# jv32_soc: IP-XACT component
VLNV kuoping:jv32:jv32_soc:1.2

## Address spaces and blocks
UART.uart_regs: base 0x20010000, range 0x20, width 32, register
CLIC.clint_regs: base 0x02000000, range 0x5000, width 32, register
MAGIC.magic_regs: base 0x40000000, range 0x08, width 32, register
CSR.csr_regs: base 0x000, range 0x1000, width 32, register

## Registers
Registers are 32-bit, read-write, no defined reset value unless marked. A register's access mark holds for its fields unless they carry their own. Offsets are from the block's base; lines under a group give offsets from that group; [hi:lo] are bit positions; {n}, {i} and the like mark numbered series; 'fields as' and 'values as' point back to an identical list; <NAME> marks a mode.

## UART.uart_regs
Base 0x20010000
0x00 DATA — TX FIFO write (write) / RX FIFO read (read)
  [7:0] DATA — Write: push byte to TX FIFO; Read: pop byte from RX FIFO
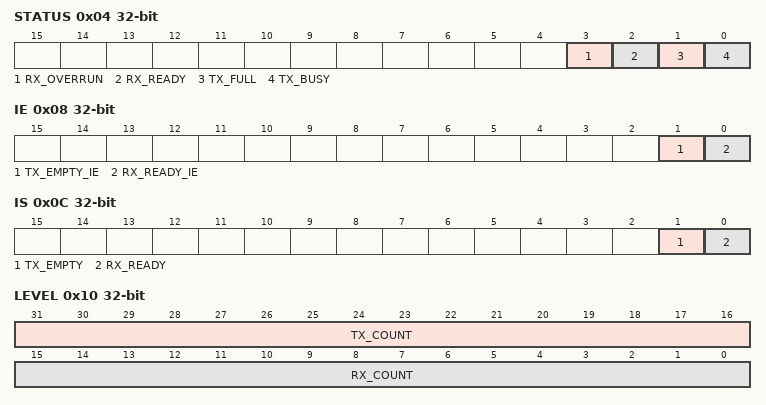
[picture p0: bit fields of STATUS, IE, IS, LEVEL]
0x04 STATUS ro — UART status flags (read-only)
  [3] RX_OVERRUN — 1 = RX FIFO full (incoming bytes will be lost)
  [2] RX_READY — 1 = RX FIFO has data available (not empty)
  [1] TX_FULL — 1 = TX FIFO full flag
  [0] TX_BUSY — 1 = TX FIFO is full (cannot accept more data)
0x08 IE — Interrupt Enable
  [1] TX_EMPTY_IE — 1 = assert IRQ when TX FIFO is empty
  [0] RX_READY_IE — 1 = assert IRQ when RX FIFO is not empty (RX_READY)
0x0C IS ro — Interrupt Status (level, read-only)
  [1] TX_EMPTY — 1 = TX FIFO empty (interrupt source)
  [0] RX_READY — 1 = RX FIFO not empty (interrupt source; level-triggered)
0x10 LEVEL — Read: FIFO fill levels ([31:16]=tx_count, [15:0]=rx_count). Write: baud-rate divisor (bits[15:0] = CLKS_PER_BIT-1; latched immediately).
  [31:16] TX_COUNT ro — Number of bytes currently in TX FIFO (read path)
  [15:0] RX_COUNT ro — Number of bytes currently in RX FIFO (read path)
0x14 CTRL — UART control register
  [0] LOOPBACK_EN — 1 = internal TX→RX loopback (for hardware test)
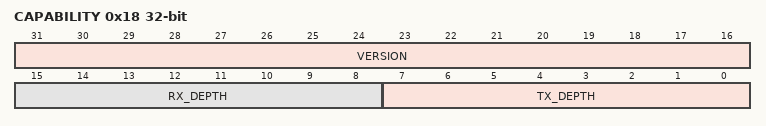
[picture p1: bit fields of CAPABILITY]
0x18 CAPABILITY ro — UART capability register (read-only). [7:0]=TX FIFO depth; [15:8]=RX FIFO depth; [31:16]=UART version (0x0001).
  [31:16] VERSION — UART hardware version (0x0001)
  [15:8] RX_DEPTH — RX FIFO depth in entries (= FIFO_DEPTH parameter, default 16)
  [7:0] TX_DEPTH — TX FIFO depth in entries (= FIFO_DEPTH parameter, default 16)

## CLIC.clint_regs
Base 0x02000000
0x00 MSIP — Machine Software Interrupt Pending
  [0] MSIP — Write 1 to assert software interrupt; write 0 to clear
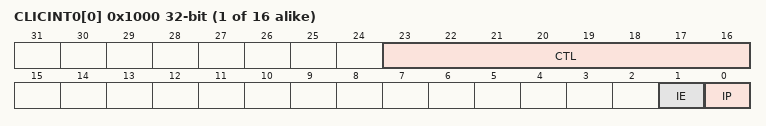
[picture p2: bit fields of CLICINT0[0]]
{0x1000+4i} CLICINT0[{i}] (i=0..15) — CLIC interrupt register for external IRQ line 0
  [23:16] CTL — Interrupt priority/level (bits [23:16] of the CLICINT word)
  [1] IE — Interrupt enable
  [0] IP ro — Interrupt pending (read-only; driven by ext_irq_i)
0x4000 MTIME_LO — Machine timer lower 32 bits (mtime[31:0]); increments every clock cycle
0x4004 MTIME_HI — Machine timer upper 32 bits (mtime[63:32])
0x4008 MTIMECMP_LO — Machine timer compare lower 32 bits; timer IRQ fires when mtime >= mtimecmp
0x400C MTIMECMP_HI — Machine timer compare upper 32 bits

## MAGIC.magic_regs
Base 0x40000000
0x00 CONSOLE wo — Write a character (byte) to simulation stdout
  [7:0] CHAR
0x04 EXIT wo — Write exit code to trigger simulation termination
  [31:0] EXIT_CODE — HTIF-encoded exit: write 1 = pass (exit code 0); write (code1)|1 = fail with code. RTL calls sim_request_exit(value1). Writing 0 has no effect.

## CSR.csr_regs
Base 0x00000000
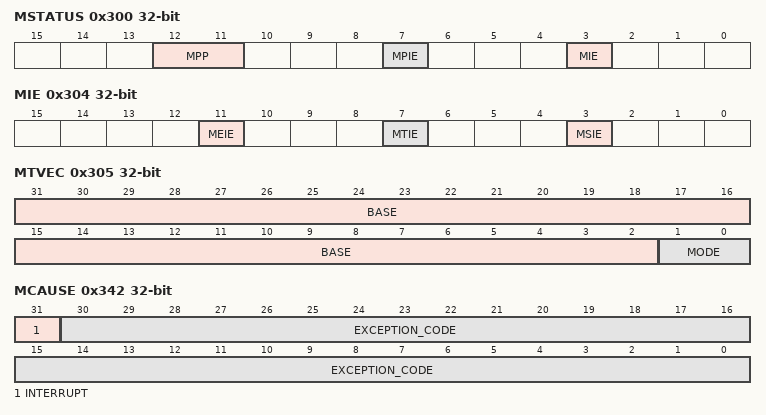
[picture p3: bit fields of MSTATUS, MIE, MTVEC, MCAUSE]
0x300 MSTATUS — Machine status register
  [12:11] MPP — Machine previous privilege mode (always 2'b11 for M-only)
  [7] MPIE — Previous MIE value (saved on trap entry)
  [3] MIE — Machine interrupt enable (global)
0x301 MISA ro reset 0x40001105 — Machine ISA register (read-only: 0x4000_1105 = RV32IMAC)
0x304 MIE — Machine interrupt enable register
  [11] MEIE — Machine external interrupt enable
  [7] MTIE — Machine timer interrupt enable
  [3] MSIE — Machine software interrupt enable
0x305 MTVEC — Machine trap-handler base address
  [31:2] BASE — Trap handler base address [31:2] (4-byte aligned)
  [1:0] MODE — Vectoring mode: 0=direct, 1=vectored, 3=CLIC
0x307 MTVT — CLIC trap-handler vector table base address
0x320 MCOUNTINHIBIT — Counter inhibit: bit0=cycle, bit2=instret
0x340 MSCRATCH — Machine scratch register
0x341 MEPC — Machine exception program counter
0x342 MCAUSE — Machine trap cause
  [31] INTERRUPT — 1 = interrupt; 0 = exception
  [30:0] EXCEPTION_CODE
0x343 MTVAL — Machine bad address or instruction
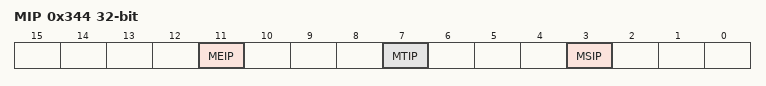
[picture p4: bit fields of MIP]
0x344 MIP ro — Machine interrupt pending (read-only view)
  [11] MEIP, [7] MTIP, [3] MSIP
0x345 MNXTI — CLIC next-interrupt CSR (atomically claim + return handler PC)
0x347 MINTTHRESH — CLIC interrupt-level threshold; interrupts below this level are masked
  [7:0] TH
0xB00 MCYCLE — Machine cycle counter (lower 32 bits)
0xB02 MINSTRET — Machine instructions-retired counter (lower 32 bits)
0xB80 MCYCLEH — Machine cycle counter (upper 32 bits)
0xB82 MINSTRETH — Machine instructions-retired counter (upper 32 bits)
0xF11 MVENDORID ro reset 0x0 — Machine vendor ID (read-only: 0x00000000)
0xF12 MARCHID ro reset 0x0 — Machine architecture ID (read-only: 0x00000000)
0xF13 MIMPID ro reset 0x0 — Machine implementation ID (read-only: 0x00000000)
0xF14 MHARTID ro reset 0x0 — Machine hardware thread ID (read-only: 0x00000000)
0xFB1 MINTSTATUS ro — CLIC current interrupt status (read-only)
  [31:24] MIL — Current machine interrupt level
